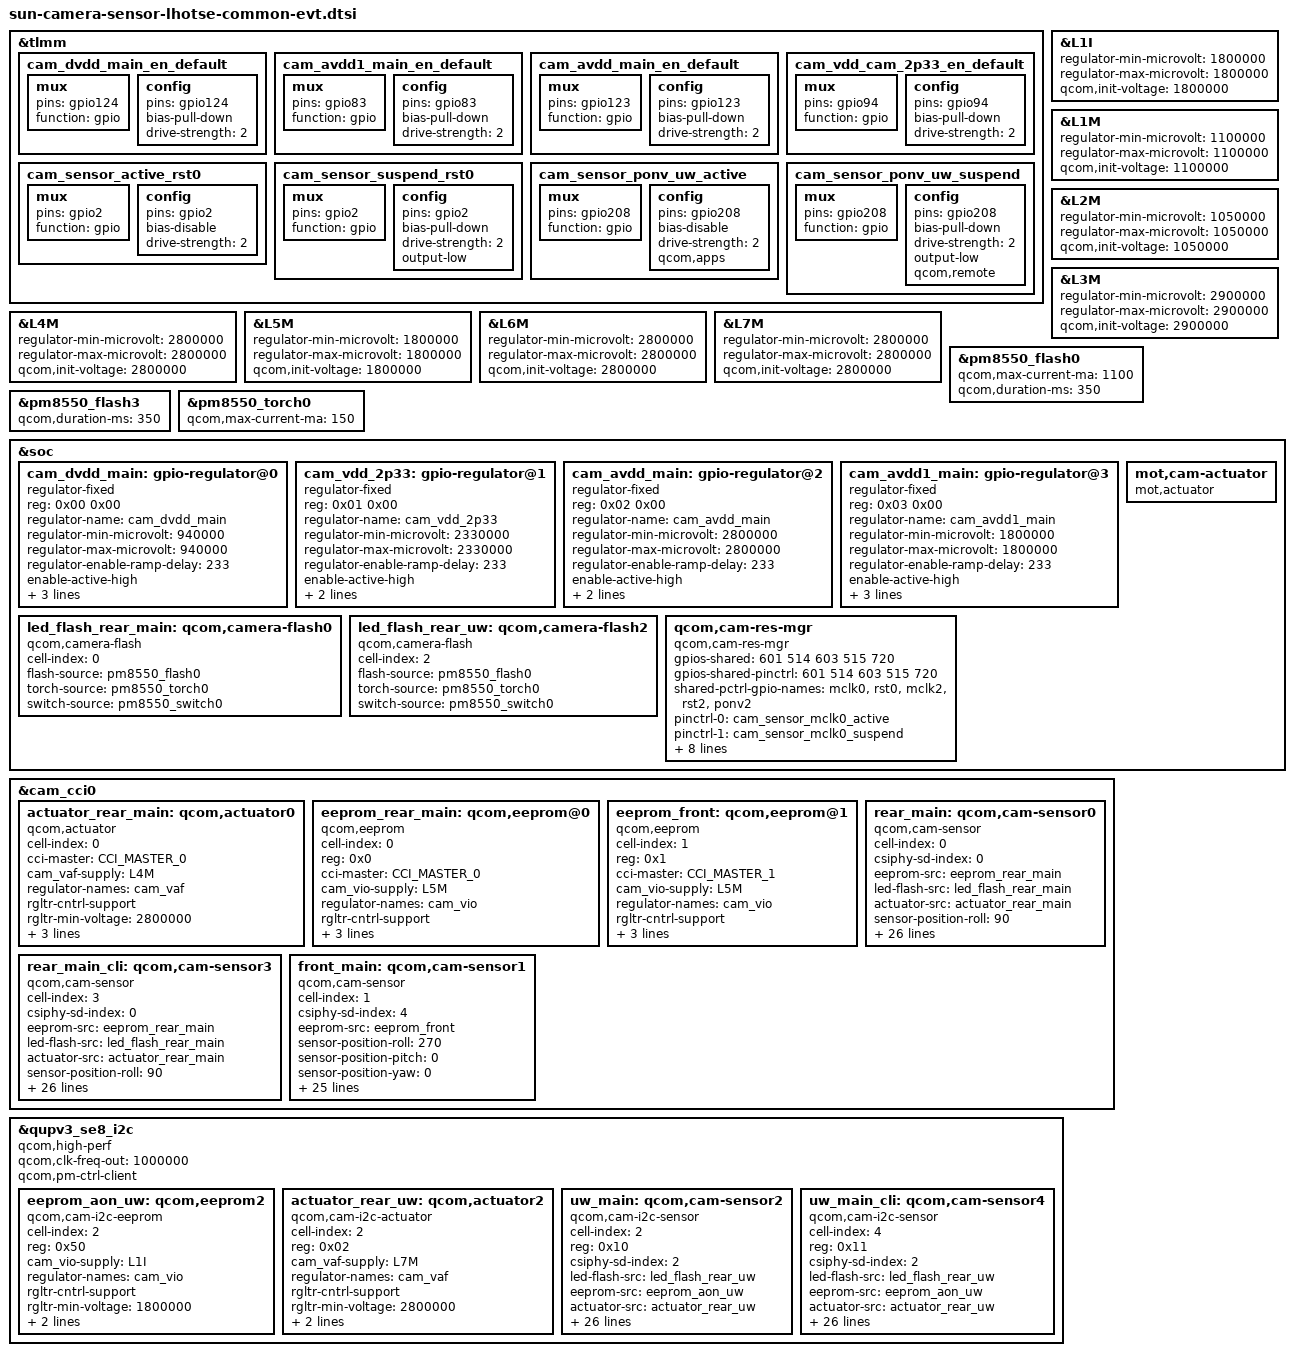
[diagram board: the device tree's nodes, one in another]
#include <dt-bindings/msm-camera.h>

&tlmm {

	cam_dvdd_main_en_default: cam_dvdd_main_en_default {
		mux {
			pins = "gpio124";
			function = "gpio";
		};

		config {
			pins = "gpio124";
			bias-pull-down; /* PULL DOWN */
			drive-strength = <2>; /* 2 MA */
		};
	};

	cam_avdd1_main_en_default: cam_avdd1_main_en_default {
		mux {
			pins = "gpio83";
			function = "gpio";
		};

		config {
			pins = "gpio83";
			bias-pull-down; /* PULL DOWN */
			drive-strength = <2>; /* 2 MA */
		};
	};

	cam_avdd_main_en_default: cam_avdd_main_en_default {
		mux {
			pins = "gpio123";
			function = "gpio";
		};

		config {
			pins = "gpio123";
			bias-pull-down; /* PULL DOWN */
			drive-strength = <2>; /* 2 MA */
		};
	};

	cam_vdd_cam_2p33_en_default: cam_vdd_cam_2p33_en_default {
		mux {
			pins = "gpio94";
			function = "gpio";
		};

		config {
			pins = "gpio94";
			bias-pull-down; /* PULL DOWN */
			drive-strength = <2>; /* 2 MA */
		};
	};

	cam_sensor_active_rst0: cam_sensor_active_rst0 {
		mux {
			pins = "gpio2";
			function = "gpio";
		};

		config {
			pins = "gpio2";
			bias-disable; /* No PULL */
			drive-strength = <2>; /* 2 MA */
		};
	};

	cam_sensor_suspend_rst0: cam_sensor_suspend_rst0 {
		mux {
			pins = "gpio2";
			function = "gpio";
		};

		config {
			pins = "gpio2";
			bias-pull-down; /* PULL DOWN */
			drive-strength = <2>; /* 2 MA */
			output-low;
		};
	};

  cam_sensor_ponv_uw_active: cam_sensor_ponv_uw_active {
		mux {
			pins = "gpio208";
			function = "gpio";
		};

		config {
			pins = "gpio208";
			bias-disable; /* No PULL */
			drive-strength = <2>; /* 2 MA */
			qcom,apps;
		};
	};

	cam_sensor_ponv_uw_suspend: cam_sensor_ponv_uw_suspend {
		mux {
			pins = "gpio208";
			function = "gpio";
		};

		config {
			pins = "gpio208";
			bias-pull-down; /* PULL DOWN */
			drive-strength = <2>; /* 2 MA */
			output-low;
			qcom,remote;
		};
	};
};

&L1I {
	regulator-min-microvolt = <1800000>;
	regulator-max-microvolt = <1800000>;
	qcom,init-voltage = <1800000>;
};

&L1M {
	regulator-min-microvolt = <1100000>;
	regulator-max-microvolt = <1100000>;
	qcom,init-voltage = <1100000>;
};

&L2M {
	regulator-min-microvolt = <1050000>;
	regulator-max-microvolt = <1050000>;
	qcom,init-voltage = <1050000>;
};

&L3M {
	regulator-min-microvolt = <2900000>;
	regulator-max-microvolt = <2900000>;
	qcom,init-voltage = <2900000>;
};

&L4M {
	regulator-min-microvolt = <2800000>;
	regulator-max-microvolt = <2800000>;
	qcom,init-voltage = <2800000>;
};

&L5M {
	regulator-min-microvolt = <1800000>;
	regulator-max-microvolt = <1800000>;
	qcom,init-voltage = <1800000>;
};

&L6M {
	regulator-min-microvolt = <2800000>;
	regulator-max-microvolt = <2800000>;
	qcom,init-voltage = <2800000>;
};

&L7M {
	regulator-min-microvolt = <2800000>;
	regulator-max-microvolt = <2800000>;
	qcom,init-voltage = <2800000>;
};

&pm8550_flash0 {
	qcom,max-current-ma = <1100>;
	qcom,duration-ms = <350>;
};
&pm8550_flash3 {
	qcom,duration-ms = <350>;
};

&pm8550_torch0 {
	qcom,max-current-ma = <150>;
};

&soc {
	cam_dvdd_main: gpio-regulator@0 {
		compatible = "regulator-fixed";
		reg = <0x00 0x00>;
		regulator-name = "cam_dvdd_main";
		regulator-min-microvolt = <940000>;
		regulator-max-microvolt = <940000>;
		regulator-enable-ramp-delay = <233>;
		enable-active-high;
		gpio = <&tlmm 124 0>;
		pinctrl-names = "default";
		pinctrl-0 = <&cam_dvdd_main_en_default>;
		vin-supply = <&S7I>;
	};

	cam_vdd_2p33: gpio-regulator@1 {
		compatible = "regulator-fixed";
		reg = <0x01 0x00>;
		regulator-name = "cam_vdd_2p33";
		regulator-min-microvolt = <2330000>;
		regulator-max-microvolt = <2330000>;
		regulator-enable-ramp-delay = <233>;
		enable-active-high;
		//regulator-always-on;
		gpio = <&tlmm 94 0>;
		pinctrl-names = "default";
		pinctrl-0 = <&cam_vdd_cam_2p33_en_default>;
		//vin-supply = <&BOB1>;
	};

	cam_avdd_main: gpio-regulator@2 {
		compatible = "regulator-fixed";
		reg = <0x02 0x00>;
		regulator-name = "cam_avdd_main";
		regulator-min-microvolt = <2800000>;
		regulator-max-microvolt = <2800000>;
		regulator-enable-ramp-delay = <233>;
		enable-active-high;
		gpio = <&tlmm 123 0>;
		pinctrl-names = "default";
		pinctrl-0 = <&cam_avdd_main_en_default>;
//		vin-supply = <&cam_vdd_2p33>;
	};

	cam_avdd1_main: gpio-regulator@3 {
		compatible = "regulator-fixed";
		reg = <0x03 0x00>;
		regulator-name = "cam_avdd1_main";
		regulator-min-microvolt = <1800000>;
		regulator-max-microvolt = <1800000>;
		regulator-enable-ramp-delay = <233>;
		enable-active-high;
		gpio = <&tlmm 83 0>;
		pinctrl-names = "default";
		pinctrl-0 = <&cam_avdd1_main_en_default>;
		vin-supply = <&S3G>;
	};

	led_flash_rear_main: qcom,camera-flash0 {
		cell-index = <0>;
		compatible = "qcom,camera-flash";
		flash-source = <&pm8550_flash0>;
		torch-source = <&pm8550_torch0>;
		switch-source = <&pm8550_switch0>;
		status = "ok";
	};

	led_flash_rear_uw: qcom,camera-flash2 {
		cell-index = <2>;
		compatible = "qcom,camera-flash";
		flash-source = <&pm8550_flash0>;
		torch-source = <&pm8550_torch0>;
		switch-source = <&pm8550_switch0>;
		status = "ok";
	};

	mot,cam-actuator {
		compatible = "mot,actuator";
		//gpio-no-mux = <0>;
		//pinctrl-names = "cam_default", "cam_suspend";
		//pinctrl-0 = <&cam_sensor_mclk1_active>;
		//pinctrl-1 = <&cam_sensor_mclk1_suspend>;
		//use-shared-clk = "true";
		//clocks = <&camcc CAM_CC_MCLK1_CLK>;
		//clock-names = "cam_clk";
		//clock-cntl-level = "nominal";
		//clock-rates = <19200000>;
		status = "ok";
	};

	qcom,cam-res-mgr {
		compatible = "qcom,cam-res-mgr";
		gpios-shared = <601 514 603 515 720>;
		gpios-shared-pinctrl = <601 514 603 515 720>;
		shared-pctrl-gpio-names = "mclk0", "rst0", "mclk2", "rst2", "ponv2";
		pinctrl-names = "mclk0_active", "mclk0_suspend", "rst0_active", "rst0_suspend", "mclk2_active", "mclk2_suspend", "rst2_active", "rst2_suspend", "ponv2_active", "ponv2_suspend";
		pinctrl-0 = <&cam_sensor_mclk0_active>;
		pinctrl-1 = <&cam_sensor_mclk0_suspend>;
		pinctrl-2 = <&cam_sensor_active_rst0>;
		pinctrl-3 = <&cam_sensor_suspend_rst0>;
		pinctrl-4 = <&cam_sensor_mclk2_active>;
		pinctrl-5 = <&cam_sensor_mclk2_suspend>;
		pinctrl-6 = <&cam_sensor_active_rst2>;
		pinctrl-7 = <&cam_sensor_suspend_rst2>;
		pinctrl-8 = <&cam_sensor_ponv_uw_active>;
		pinctrl-9 = <&cam_sensor_ponv_uw_suspend>;
		status = "ok";
	};
};

&cam_cci0 {
	actuator_rear_main: qcom,actuator0 {
		cell-index = <0>;
		compatible = "qcom,actuator";
		cci-master = <CCI_MASTER_0>;
		cam_vaf-supply = <&L4M>;
		regulator-names = "cam_vaf";
		rgltr-cntrl-support;
		rgltr-min-voltage = <2800000>;
		rgltr-max-voltage = <2800000>;
		rgltr-load-current = <119000>;
		status = "ok";
		multi-user-support;
	};

	eeprom_rear_main: qcom,eeprom@0 {
		cell-index = <0>;
		reg = <0x0>;
		compatible = "qcom,eeprom";
		cci-master = <CCI_MASTER_0>;
		cam_vio-supply = <&L5M>;
		regulator-names = "cam_vio";
		rgltr-cntrl-support;
		rgltr-min-voltage = <1800000>;
		rgltr-max-voltage = <1800000>;
		rgltr-load-current = <0>;
		status = "ok";
	};

	eeprom_front: qcom,eeprom@1 {
		cell-index = <1>;
		reg = <0x1>;
		compatible = "qcom,eeprom";
		cci-master = <CCI_MASTER_1>;
		cam_vio-supply = <&L5M>;
		regulator-names = "cam_vio";
		rgltr-cntrl-support;
		rgltr-min-voltage = <1800000>;
		rgltr-max-voltage = <1800000>;
		rgltr-load-current = <0>;
		status = "ok";
	};

	rear_main: qcom,cam-sensor0 {
		cell-index = <0>;
		compatible = "qcom,cam-sensor";
		csiphy-sd-index = <0>;
		eeprom-src = <&eeprom_rear_main>;
		led-flash-src = <&led_flash_rear_main>;
		actuator-src = <&actuator_rear_main>;
		sensor-position-roll = <90>;
		sensor-position-pitch = <0>;
		sensor-position-yaw = <180>;
		cam_vio-supply = <&L5M>;
		cam_vdig-supply = <&cam_dvdd_main>;
		cam_clk-supply = <&cam_cc_titan_top_gdsc>;
		cam_vana-supply = <&cam_avdd_main>;
		cam_v_custom1-supply = <&cam_avdd1_main>;
		regulator-names = "cam_vio",
			"cam_vdig","cam_clk","cam_vana","cam_v_custom1";
		rgltr-cntrl-support;
		rgltr-min-voltage = <1800000 940000 0 2800000 1800000>;
		rgltr-max-voltage = <1800000 940000 0 2800000 1800000>;
		rgltr-load-current = <5000 544000 0 10000 39000>;
		gpio-no-mux = <0>;
		//pinctrl-names = "cam_default", "cam_suspend";
		//pinctrl-0 = <&cam_sensor_mclk0_active
		//	&cam_sensor_active_rst0>;
		//pinctrl-1 = <&cam_sensor_mclk0_suspend
		//	&cam_sensor_suspend_rst0>;
		gpios = <&tlmm 89 0>,
			<&tlmm 2 0>;
		gpio-reset = <1>;
		gpio-req-tbl-num = <0 1>;
		gpio-req-tbl-flags = <1 0>;
		gpio-req-tbl-label = "CAMIF_MCLK0",
					"CAM_RESET0";
		cci-master = <CCI_MASTER_0>;
		clocks = <&cambistmclkcc CAM_BIST_MCLK_CC_MCLK0_CLK>;
		clock-names = "cam_clk";
		clock-cntl-level = "nominal";
		clock-rates = <24000000>;
		status = "ok";
	};

	rear_main_cli: qcom,cam-sensor3 {
		cell-index = <3>;
		compatible = "qcom,cam-sensor";
		csiphy-sd-index = <0>;
		eeprom-src = <&eeprom_rear_main>;
		led-flash-src = <&led_flash_rear_main>;
		actuator-src = <&actuator_rear_main>;
		sensor-position-roll = <90>;
		sensor-position-pitch = <0>;
		sensor-position-yaw = <180>;
		cam_vio-supply = <&L5M>;
		cam_vdig-supply = <&cam_dvdd_main>;
		cam_clk-supply = <&cam_cc_titan_top_gdsc>;
		cam_vana-supply = <&cam_avdd_main>;
		cam_v_custom1-supply = <&cam_avdd1_main>;
		regulator-names = "cam_vio",
			"cam_vdig","cam_clk","cam_vana","cam_v_custom1";
		rgltr-cntrl-support;
		rgltr-min-voltage = <1800000 940000 0 2800000 1800000>;
		rgltr-max-voltage = <1800000 940000 0 2800000 1800000>;
		rgltr-load-current = <5000 544000 0 10000 39000>;
		gpio-no-mux = <0>;
		//pinctrl-names = "cam_default", "cam_suspend";
		//pinctrl-0 = <&cam_sensor_mclk0_active
		//	&cam_sensor_active_rst0>;
		//pinctrl-1 = <&cam_sensor_mclk0_suspend
		//	&cam_sensor_suspend_rst0>;
		gpios = <&tlmm 89 0>,
			<&tlmm 2 0>;
		gpio-reset = <1>;
		gpio-req-tbl-num = <0 1>;
		gpio-req-tbl-flags = <1 0>;
		gpio-req-tbl-label = "CAMIF_MCLK0",
					"CAM_RESET0";
		cci-master = <CCI_MASTER_0>;
		clocks = <&cambistmclkcc CAM_BIST_MCLK_CC_MCLK0_CLK>;
		clock-names = "cam_clk";
		clock-cntl-level = "nominal";
		clock-rates = <24000000>;
		status = "ok";
	};

	front_main: qcom,cam-sensor1 {
		cell-index = <1>;
		compatible = "qcom,cam-sensor";
		csiphy-sd-index = <4>;
		eeprom-src = <&eeprom_front>;
		sensor-position-roll = <270>;
		sensor-position-pitch = <0>;
		sensor-position-yaw = <0>;
		cam_vio-supply = <&L5M>;
		cam_vdig-supply = <&L2M>;
		cam_clk-supply = <&cam_cc_titan_top_gdsc>;
		cam_vana-supply = <&L6M>;
		regulator-names = "cam_vio", "cam_vdig","cam_clk", "cam_vana";
		rgltr-cntrl-support;
		rgltr-min-voltage = <1800000 1050000 0 2800000>;
		rgltr-max-voltage = <1800000 1050000 0 2800000>;
		rgltr-load-current = <3000 283000 0  50000>;
		gpio-no-mux = <0>;
		pinctrl-names = "cam_default", "cam_suspend";
		pinctrl-0 = <&cam_sensor_mclk4_active
				 &cam_sensor_active_rst4>;
		pinctrl-1 = <&cam_sensor_mclk4_suspend
				 &cam_sensor_suspend_rst4>;
		gpios = <&tlmm 93 0>,
			<&tlmm 7 0>;
		gpio-reset = <1>;
		gpio-req-tbl-num = <0 1>;
		gpio-req-tbl-flags = <1 0>;
		gpio-req-tbl-label = "CAMIF_MCLK4",
					"CAM_RESET4";
		cci-master = <CCI_MASTER_1>;
		clocks = <&cambistmclkcc CAM_BIST_MCLK_CC_MCLK4_CLK>;
		clock-names = "cam_clk";
		clock-cntl-level = "nominal";
		clock-rates = <24000000>;
		status = "ok";
	};
};

&qupv3_se8_i2c {
	status = "ok";
	qcom,high-perf;
	qcom,clk-freq-out = <1000000>;
	qcom,pm-ctrl-client;

	eeprom_aon_uw: qcom,eeprom2 {
		cell-index = <2>;
		reg = <0x50>;
		compatible = "qcom,cam-i2c-eeprom";
		cam_vio-supply = <&L1I>;
		regulator-names = "cam_vio";
		rgltr-cntrl-support;
		rgltr-min-voltage = <1800000>;
		rgltr-max-voltage = <1800000>;
		rgltr-load-current = <6000>;
		status = "ok";
	};

	actuator_rear_uw: qcom,actuator2 {
		cell-index = <2>;
		compatible = "qcom,cam-i2c-actuator";
		reg = <0x02>;
		cam_vaf-supply = <&L7M>;
		regulator-names = "cam_vaf";
		rgltr-cntrl-support;
		rgltr-min-voltage = <2800000>;
		rgltr-max-voltage = <2800000>;
		rgltr-load-current = <119000>;
		status = "ok";
	};

	uw_main: qcom,cam-sensor2 {
		cell-index = <2>;
		reg = <0x10>;
		compatible = "qcom,cam-i2c-sensor";
		csiphy-sd-index = <2>;
		led-flash-src = <&led_flash_rear_uw>;
		eeprom-src = <&eeprom_aon_uw>;
		actuator-src = <&actuator_rear_uw>;
		sensor-position-roll = <90>;
		sensor-position-pitch = <0>;
		sensor-position-yaw = <180>;
		cam_vio-supply = <&L1I>;
		cam_vdig-supply = <&L1M>;
		cam_clk-supply = <&cam_cc_titan_top_gdsc>;
		cam_vana-supply = <&L3M>;
		regulator-names = "cam_vio", "cam_vdig","cam_clk", "cam_vana";
		rgltr-cntrl-support;
		aon-camera-id = <AON_CAM2>;
		rgltr-min-voltage = <1800000 1100000 0 2900000>;
		rgltr-max-voltage = <1800000 1100000 0 2900000>;
		rgltr-load-current = <3000 283000 0  50000>;
		gpio-no-mux = <0>;
		//pinctrl-names = "cam_default", "cam_suspend";
		//pinctrl-0 = <&cam_sensor_mclk2_active
		//		 &cam_sensor_active_rst2
		//		 &cam_sensor_ponv_uw_active>;
		//pinctrl-1 = <&cam_sensor_mclk2_suspend
		//		 &cam_sensor_suspend_rst2
		//		 &cam_sensor_ponv_uw_suspend>;
		gpios = <&tlmm 91 0>,
			<&tlmm 3 0>,
			<&tlmm 208 0>;
		gpio-reset = <1>;
		gpio-standby = <2>;
		gpio-req-tbl-num = <0 1 2>;
		gpio-req-tbl-flags = <1 0 0>;
		gpio-req-tbl-label = "CAMIF_MCLK2","CAM_RESET2","CAM_STANDBY";
		clocks = <&cambistmclkcc CAM_BIST_MCLK_CC_MCLK2_CLK>;
		clock-names = "cam_clk";
		clock-cntl-level = "nominal";
		clock-rates = <19200000>;
		status = "ok";
	};

	uw_main_cli: qcom,cam-sensor4 {
		cell-index = <4>;
		reg = <0x11>;
		compatible = "qcom,cam-i2c-sensor";
		csiphy-sd-index = <2>;
		led-flash-src = <&led_flash_rear_uw>;
		eeprom-src = <&eeprom_aon_uw>;
		actuator-src = <&actuator_rear_uw>;
		sensor-position-roll = <90>;
		sensor-position-pitch = <0>;
		sensor-position-yaw = <180>;
		cam_vio-supply = <&L1I>;
		cam_vdig-supply = <&L1M>;
		cam_clk-supply = <&cam_cc_titan_top_gdsc>;
		cam_vana-supply = <&L3M>;
		regulator-names = "cam_vio", "cam_vdig","cam_clk", "cam_vana";
		rgltr-cntrl-support;
		aon-camera-id = <AON_CAM2>;
		rgltr-min-voltage = <1800000 1100000 0 2900000>;
		rgltr-max-voltage = <1800000 1100000 0 2900000>;
		rgltr-load-current = <3000 283000 0  50000>;
		gpio-no-mux = <0>;
		//pinctrl-names = "cam_default", "cam_suspend";
		//pinctrl-0 = <&cam_sensor_mclk2_active
		//		 &cam_sensor_active_rst2
		//		 &cam_sensor_ponv_uw_active>;
		//pinctrl-1 = <&cam_sensor_mclk2_suspend
		//		 &cam_sensor_suspend_rst2
		//		 &cam_sensor_ponv_uw_suspend>;
		gpios = <&tlmm 91 0>,
			<&tlmm 3 0>,
			<&tlmm 208 0>;
		gpio-reset = <1>;
		gpio-standby = <2>;
		gpio-req-tbl-num = <0 1 2>;
		gpio-req-tbl-flags = <1 0 0>;
		gpio-req-tbl-label = "CAMIF_MCLK2","CAM_RESET2","CAM_STANDBY";
		clocks = <&cambistmclkcc CAM_BIST_MCLK_CC_MCLK2_CLK>;
		clock-names = "cam_clk";
		clock-cntl-level = "nominal";
		clock-rates = <19200000>;
		status = "ok";
	};
};
